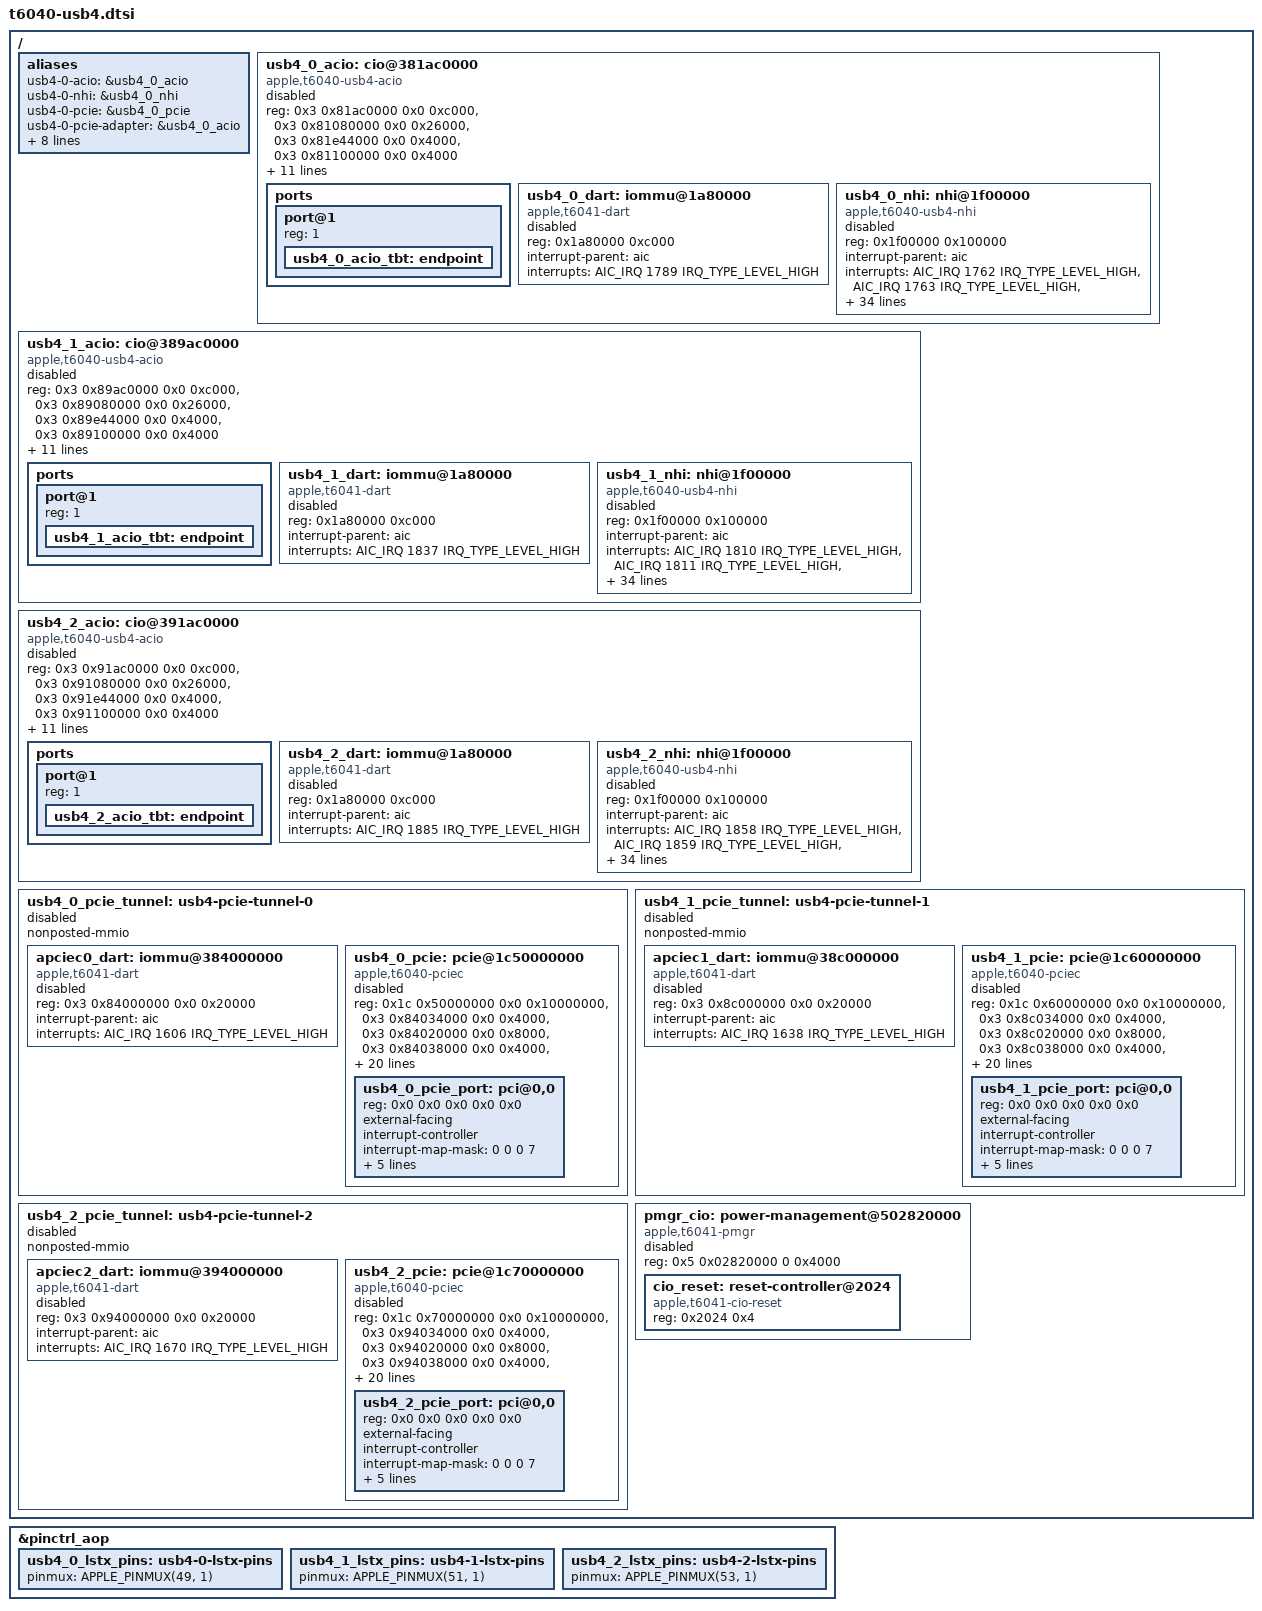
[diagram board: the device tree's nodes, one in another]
// SPDX-License-Identifier: GPL-2.0+ OR MIT
/*
 * T6040 USB4/PCIe-C resource description.
 *
 * Every node is disabled here; a board enables the routers it has qualified.
 */

/ {
	aliases {
		usb4-0-acio = &usb4_0_acio;
		usb4-0-nhi = &usb4_0_nhi;
		usb4-0-pcie = &usb4_0_pcie;
		usb4-0-pcie-adapter = &usb4_0_acio;
		usb4-1-acio = &usb4_1_acio;
		usb4-1-nhi = &usb4_1_nhi;
		usb4-1-pcie = &usb4_1_pcie;
		usb4-1-pcie-adapter = &usb4_1_acio;
		usb4-2-acio = &usb4_2_acio;
		usb4-2-nhi = &usb4_2_nhi;
		usb4-2-pcie = &usb4_2_pcie;
		usb4-2-pcie-adapter = &usb4_2_acio;
	};

	usb4_0_acio: cio@381ac0000 {
		compatible = "apple,t6040-usb4-acio";
		reg = <0x3 0x81ac0000 0x0 0xc000>,
		      <0x3 0x81080000 0x0 0x26000>,
		      <0x3 0x81e44000 0x0 0x4000>,
		      <0x3 0x81100000 0x0 0x4000>;
		reg-names = "rc", "sram", "pcie-adapter", "cpu";
		interrupt-parent = <&aic>;
		interrupts = <AIC_IRQ 1791 IRQ_TYPE_LEVEL_HIGH>;
		interrupt-names = "sram-parity";
		mboxes = <&usb4_0_mbox>;
		resets = <&cio_reset 0>;
		pinctrl-names = "lstx";
		pinctrl-0 = <&usb4_0_lstx_pins>;
		lstx-gpios = <&pinctrl_aop 49 GPIO_ACTIVE_HIGH>;
		power-domains = <&ps_atc0_cio>, <&ps_atc0_cio_pcie>,
				<&ps_atc0_cio_usb>, <&ps_atc0_pcie>;
		thunderbolt-switch;
		apple,pcie-tunnel = <&usb4_0_pcie_tunnel>;
		#address-cells = <1>;
		#size-cells = <1>;
		ranges = <0x0 0x3 0x80000000 0x2000000>;
		nonposted-mmio;
		status = "disabled";

		ports {
			#address-cells = <1>;
			#size-cells = <0>;

			port@1 {
				reg = <1>;
				usb4_0_acio_tbt: endpoint { };
			};
		};

		usb4_0_dart: iommu@1a80000 {
			compatible = "apple,t6041-dart", "apple,t8110-dart";
			reg = <0x1a80000 0xc000>;
			#iommu-cells = <1>;
			interrupt-parent = <&aic>;
			interrupts = <AIC_IRQ 1789 IRQ_TYPE_LEVEL_HIGH>;
			status = "disabled";
		};

		usb4_0_nhi: nhi@1f00000 {
			compatible = "apple,t6040-usb4-nhi";
			reg = <0x1f00000 0x100000>;
			reg-names = "nhi";
			interrupt-parent = <&aic>;
			interrupts = <AIC_IRQ 1762 IRQ_TYPE_LEVEL_HIGH>,
				     <AIC_IRQ 1763 IRQ_TYPE_LEVEL_HIGH>,
				     <AIC_IRQ 1764 IRQ_TYPE_LEVEL_HIGH>,
				     <AIC_IRQ 1765 IRQ_TYPE_LEVEL_HIGH>,
				     <AIC_IRQ 1766 IRQ_TYPE_LEVEL_HIGH>,
				     <AIC_IRQ 1767 IRQ_TYPE_LEVEL_HIGH>,
				     <AIC_IRQ 1768 IRQ_TYPE_LEVEL_HIGH>,
				     <AIC_IRQ 1769 IRQ_TYPE_LEVEL_HIGH>,
				     <AIC_IRQ 1770 IRQ_TYPE_LEVEL_HIGH>,
				     <AIC_IRQ 1771 IRQ_TYPE_LEVEL_HIGH>,
				     <AIC_IRQ 1772 IRQ_TYPE_LEVEL_HIGH>,
				     <AIC_IRQ 1773 IRQ_TYPE_LEVEL_HIGH>,
				     <AIC_IRQ 1774 IRQ_TYPE_LEVEL_HIGH>,
				     <AIC_IRQ 1775 IRQ_TYPE_LEVEL_HIGH>,
				     <AIC_IRQ 1776 IRQ_TYPE_LEVEL_HIGH>,
				     <AIC_IRQ 1777 IRQ_TYPE_LEVEL_HIGH>,
				     <AIC_IRQ 1778 IRQ_TYPE_LEVEL_HIGH>,
				     <AIC_IRQ 1779 IRQ_TYPE_LEVEL_HIGH>,
				     <AIC_IRQ 1780 IRQ_TYPE_LEVEL_HIGH>,
				     <AIC_IRQ 1781 IRQ_TYPE_LEVEL_HIGH>,
				     <AIC_IRQ 1782 IRQ_TYPE_LEVEL_HIGH>,
				     <AIC_IRQ 1783 IRQ_TYPE_LEVEL_HIGH>,
				     <AIC_IRQ 1784 IRQ_TYPE_LEVEL_HIGH>,
				     <AIC_IRQ 1785 IRQ_TYPE_LEVEL_HIGH>;
			interrupt-names = "txring0", "txring1", "txring2", "txring3",
					  "txring4", "txring5", "txring6", "txring7",
					  "txring8", "txring9", "txring10", "txring11",
					  "rxring0", "rxring1", "rxring2", "rxring3",
					  "rxring4", "rxring5", "rxring6", "rxring7",
					  "rxring8", "rxring9", "rxring10", "rxring11";
			iommus = <&usb4_0_dart 0>, <&usb4_0_dart 1>,
				 <&usb4_0_dart 2>, <&usb4_0_dart 3>,
				 <&usb4_0_dart 4>, <&usb4_0_dart 5>,
				 <&usb4_0_dart 6>, <&usb4_0_dart 7>,
				 <&usb4_0_dart 8>, <&usb4_0_dart 9>,
				 <&usb4_0_dart 10>, <&usb4_0_dart 11>,
				 <&usb4_0_dart 16>, <&usb4_0_dart 17>,
				 <&usb4_0_dart 18>, <&usb4_0_dart 19>,
				 <&usb4_0_dart 20>, <&usb4_0_dart 21>,
				 <&usb4_0_dart 22>, <&usb4_0_dart 23>,
				 <&usb4_0_dart 24>, <&usb4_0_dart 25>,
				 <&usb4_0_dart 26>, <&usb4_0_dart 27>;
			/* To be filled by the loader. */
			apple,thunderbolt-drom = [00];
			status = "disabled";
		};
	};

	usb4_1_acio: cio@389ac0000 {
		compatible = "apple,t6040-usb4-acio";
		reg = <0x3 0x89ac0000 0x0 0xc000>,
		      <0x3 0x89080000 0x0 0x26000>,
		      <0x3 0x89e44000 0x0 0x4000>,
		      <0x3 0x89100000 0x0 0x4000>;
		reg-names = "rc", "sram", "pcie-adapter", "cpu";
		interrupt-parent = <&aic>;
		interrupts = <AIC_IRQ 1839 IRQ_TYPE_LEVEL_HIGH>;
		interrupt-names = "sram-parity";
		mboxes = <&usb4_1_mbox>;
		resets = <&cio_reset 1>;
		pinctrl-names = "lstx";
		pinctrl-0 = <&usb4_1_lstx_pins>;
		lstx-gpios = <&pinctrl_aop 51 GPIO_ACTIVE_HIGH>;
		power-domains = <&ps_atc1_cio>, <&ps_atc1_cio_pcie>,
				<&ps_atc1_cio_usb>, <&ps_atc1_pcie>;
		thunderbolt-switch;
		apple,pcie-tunnel = <&usb4_1_pcie_tunnel>;
		#address-cells = <1>;
		#size-cells = <1>;
		ranges = <0x0 0x3 0x88000000 0x2000000>;
		nonposted-mmio;
		status = "disabled";

		ports {
			#address-cells = <1>;
			#size-cells = <0>;

			port@1 {
				reg = <1>;
				usb4_1_acio_tbt: endpoint { };
			};
		};

		usb4_1_dart: iommu@1a80000 {
			compatible = "apple,t6041-dart", "apple,t8110-dart";
			reg = <0x1a80000 0xc000>;
			#iommu-cells = <1>;
			interrupt-parent = <&aic>;
			interrupts = <AIC_IRQ 1837 IRQ_TYPE_LEVEL_HIGH>;
			status = "disabled";
		};

		usb4_1_nhi: nhi@1f00000 {
			compatible = "apple,t6040-usb4-nhi";
			reg = <0x1f00000 0x100000>;
			reg-names = "nhi";
			interrupt-parent = <&aic>;
			interrupts = <AIC_IRQ 1810 IRQ_TYPE_LEVEL_HIGH>,
				     <AIC_IRQ 1811 IRQ_TYPE_LEVEL_HIGH>,
				     <AIC_IRQ 1812 IRQ_TYPE_LEVEL_HIGH>,
				     <AIC_IRQ 1813 IRQ_TYPE_LEVEL_HIGH>,
				     <AIC_IRQ 1814 IRQ_TYPE_LEVEL_HIGH>,
				     <AIC_IRQ 1815 IRQ_TYPE_LEVEL_HIGH>,
				     <AIC_IRQ 1816 IRQ_TYPE_LEVEL_HIGH>,
				     <AIC_IRQ 1817 IRQ_TYPE_LEVEL_HIGH>,
				     <AIC_IRQ 1818 IRQ_TYPE_LEVEL_HIGH>,
				     <AIC_IRQ 1819 IRQ_TYPE_LEVEL_HIGH>,
				     <AIC_IRQ 1820 IRQ_TYPE_LEVEL_HIGH>,
				     <AIC_IRQ 1821 IRQ_TYPE_LEVEL_HIGH>,
				     <AIC_IRQ 1822 IRQ_TYPE_LEVEL_HIGH>,
				     <AIC_IRQ 1823 IRQ_TYPE_LEVEL_HIGH>,
				     <AIC_IRQ 1824 IRQ_TYPE_LEVEL_HIGH>,
				     <AIC_IRQ 1825 IRQ_TYPE_LEVEL_HIGH>,
				     <AIC_IRQ 1826 IRQ_TYPE_LEVEL_HIGH>,
				     <AIC_IRQ 1827 IRQ_TYPE_LEVEL_HIGH>,
				     <AIC_IRQ 1828 IRQ_TYPE_LEVEL_HIGH>,
				     <AIC_IRQ 1829 IRQ_TYPE_LEVEL_HIGH>,
				     <AIC_IRQ 1830 IRQ_TYPE_LEVEL_HIGH>,
				     <AIC_IRQ 1831 IRQ_TYPE_LEVEL_HIGH>,
				     <AIC_IRQ 1832 IRQ_TYPE_LEVEL_HIGH>,
				     <AIC_IRQ 1833 IRQ_TYPE_LEVEL_HIGH>;
			interrupt-names = "txring0", "txring1", "txring2", "txring3",
					  "txring4", "txring5", "txring6", "txring7",
					  "txring8", "txring9", "txring10", "txring11",
					  "rxring0", "rxring1", "rxring2", "rxring3",
					  "rxring4", "rxring5", "rxring6", "rxring7",
					  "rxring8", "rxring9", "rxring10", "rxring11";
			iommus = <&usb4_1_dart 0>, <&usb4_1_dart 1>,
				 <&usb4_1_dart 2>, <&usb4_1_dart 3>,
				 <&usb4_1_dart 4>, <&usb4_1_dart 5>,
				 <&usb4_1_dart 6>, <&usb4_1_dart 7>,
				 <&usb4_1_dart 8>, <&usb4_1_dart 9>,
				 <&usb4_1_dart 10>, <&usb4_1_dart 11>,
				 <&usb4_1_dart 16>, <&usb4_1_dart 17>,
				 <&usb4_1_dart 18>, <&usb4_1_dart 19>,
				 <&usb4_1_dart 20>, <&usb4_1_dart 21>,
				 <&usb4_1_dart 22>, <&usb4_1_dart 23>,
				 <&usb4_1_dart 24>, <&usb4_1_dart 25>,
				 <&usb4_1_dart 26>, <&usb4_1_dart 27>;
			/* To be filled by the loader. */
			apple,thunderbolt-drom = [00];
			status = "disabled";
		};
	};

	usb4_2_acio: cio@391ac0000 {
		compatible = "apple,t6040-usb4-acio";
		reg = <0x3 0x91ac0000 0x0 0xc000>,
		      <0x3 0x91080000 0x0 0x26000>,
		      <0x3 0x91e44000 0x0 0x4000>,
		      <0x3 0x91100000 0x0 0x4000>;
		reg-names = "rc", "sram", "pcie-adapter", "cpu";
		interrupt-parent = <&aic>;
		interrupts = <AIC_IRQ 1887 IRQ_TYPE_LEVEL_HIGH>;
		interrupt-names = "sram-parity";
		mboxes = <&usb4_2_mbox>;
		resets = <&cio_reset 2>;
		pinctrl-names = "lstx";
		pinctrl-0 = <&usb4_2_lstx_pins>;
		lstx-gpios = <&pinctrl_aop 53 GPIO_ACTIVE_HIGH>;
		power-domains = <&ps_atc2_cio>, <&ps_atc2_cio_pcie>,
				<&ps_atc2_cio_usb>, <&ps_atc2_pcie>;
		thunderbolt-switch;
		apple,pcie-tunnel = <&usb4_2_pcie_tunnel>;
		#address-cells = <1>;
		#size-cells = <1>;
		ranges = <0x0 0x3 0x90000000 0x2000000>;
		nonposted-mmio;
		status = "disabled";

		ports {
			#address-cells = <1>;
			#size-cells = <0>;

			port@1 {
				reg = <1>;
				usb4_2_acio_tbt: endpoint { };
			};
		};

		usb4_2_dart: iommu@1a80000 {
			compatible = "apple,t6041-dart", "apple,t8110-dart";
			reg = <0x1a80000 0xc000>;
			#iommu-cells = <1>;
			interrupt-parent = <&aic>;
			interrupts = <AIC_IRQ 1885 IRQ_TYPE_LEVEL_HIGH>;
			status = "disabled";
		};

		usb4_2_nhi: nhi@1f00000 {
			compatible = "apple,t6040-usb4-nhi";
			reg = <0x1f00000 0x100000>;
			reg-names = "nhi";
			interrupt-parent = <&aic>;
			interrupts = <AIC_IRQ 1858 IRQ_TYPE_LEVEL_HIGH>,
				     <AIC_IRQ 1859 IRQ_TYPE_LEVEL_HIGH>,
				     <AIC_IRQ 1860 IRQ_TYPE_LEVEL_HIGH>,
				     <AIC_IRQ 1861 IRQ_TYPE_LEVEL_HIGH>,
				     <AIC_IRQ 1862 IRQ_TYPE_LEVEL_HIGH>,
				     <AIC_IRQ 1863 IRQ_TYPE_LEVEL_HIGH>,
				     <AIC_IRQ 1864 IRQ_TYPE_LEVEL_HIGH>,
				     <AIC_IRQ 1865 IRQ_TYPE_LEVEL_HIGH>,
				     <AIC_IRQ 1866 IRQ_TYPE_LEVEL_HIGH>,
				     <AIC_IRQ 1867 IRQ_TYPE_LEVEL_HIGH>,
				     <AIC_IRQ 1868 IRQ_TYPE_LEVEL_HIGH>,
				     <AIC_IRQ 1869 IRQ_TYPE_LEVEL_HIGH>,
				     <AIC_IRQ 1870 IRQ_TYPE_LEVEL_HIGH>,
				     <AIC_IRQ 1871 IRQ_TYPE_LEVEL_HIGH>,
				     <AIC_IRQ 1872 IRQ_TYPE_LEVEL_HIGH>,
				     <AIC_IRQ 1873 IRQ_TYPE_LEVEL_HIGH>,
				     <AIC_IRQ 1874 IRQ_TYPE_LEVEL_HIGH>,
				     <AIC_IRQ 1875 IRQ_TYPE_LEVEL_HIGH>,
				     <AIC_IRQ 1876 IRQ_TYPE_LEVEL_HIGH>,
				     <AIC_IRQ 1877 IRQ_TYPE_LEVEL_HIGH>,
				     <AIC_IRQ 1878 IRQ_TYPE_LEVEL_HIGH>,
				     <AIC_IRQ 1879 IRQ_TYPE_LEVEL_HIGH>,
				     <AIC_IRQ 1880 IRQ_TYPE_LEVEL_HIGH>,
				     <AIC_IRQ 1881 IRQ_TYPE_LEVEL_HIGH>;
			interrupt-names = "txring0", "txring1", "txring2", "txring3",
					  "txring4", "txring5", "txring6", "txring7",
					  "txring8", "txring9", "txring10", "txring11",
					  "rxring0", "rxring1", "rxring2", "rxring3",
					  "rxring4", "rxring5", "rxring6", "rxring7",
					  "rxring8", "rxring9", "rxring10", "rxring11";
			iommus = <&usb4_2_dart 0>, <&usb4_2_dart 1>,
				 <&usb4_2_dart 2>, <&usb4_2_dart 3>,
				 <&usb4_2_dart 4>, <&usb4_2_dart 5>,
				 <&usb4_2_dart 6>, <&usb4_2_dart 7>,
				 <&usb4_2_dart 8>, <&usb4_2_dart 9>,
				 <&usb4_2_dart 10>, <&usb4_2_dart 11>,
				 <&usb4_2_dart 16>, <&usb4_2_dart 17>,
				 <&usb4_2_dart 18>, <&usb4_2_dart 19>,
				 <&usb4_2_dart 20>, <&usb4_2_dart 21>,
				 <&usb4_2_dart 22>, <&usb4_2_dart 23>,
				 <&usb4_2_dart 24>, <&usb4_2_dart 25>,
				 <&usb4_2_dart 26>, <&usb4_2_dart 27>;
			/* To be filled by the loader. */
			apple,thunderbolt-drom = [00];
			status = "disabled";
		};
	};

	usb4_0_pcie_tunnel: usb4-pcie-tunnel-0 {
		#address-cells = <2>;
		#size-cells = <2>;
		ranges;
		nonposted-mmio;
		status = "disabled";

		apciec0_dart: iommu@384000000 {
			compatible = "apple,t6041-dart", "apple,t8110-dart";
			reg = <0x3 0x84000000 0x0 0x20000>;
			interrupt-parent = <&aic>;
			interrupts = <AIC_IRQ 1606 IRQ_TYPE_LEVEL_HIGH>;
			#iommu-cells = <1>;
			status = "disabled";
		};

		usb4_0_pcie: pcie@1c50000000 {
			compatible = "apple,t6040-pciec";
			device_type = "pci";
			reg = <0x1c 0x50000000 0x0 0x10000000>,
			      <0x3 0x84034000 0x0 0x4000>,
			      <0x3 0x84020000 0x0 0x8000>,
			      <0x3 0x84038000 0x0 0x4000>,
			      <0x3 0x84060000 0x0 0x4000>,
			      <0x3 0x80020000 0x0 0x4000>,
			      <0x3 0x8402c000 0x0 0x4000>,
			      <0x3 0x84028000 0x0 0x4000>;
			reg-names = "config", "rc", "port0", "fabric", "debug",
				    "ioa", "ltssm", "intr2axi";
			interrupt-parent = <&aic>;
			interrupts = <AIC_IRQ 1605 IRQ_TYPE_LEVEL_HIGH>,
				     <AIC_IRQ 1608 IRQ_TYPE_LEVEL_HIGH>,
				     <AIC_IRQ 1609 IRQ_TYPE_LEVEL_HIGH>,
				     <AIC_IRQ 1610 IRQ_TYPE_LEVEL_HIGH>,
				     <AIC_IRQ 1611 IRQ_TYPE_LEVEL_HIGH>,
				     <AIC_IRQ 1612 IRQ_TYPE_LEVEL_HIGH>;
			interrupt-names = "port", "intx-a", "intx-b", "intx-c",
					  "intx-d", "parity";
			power-domains = <&ps_atc0_pcie>;
			msi-controller;
			msi-parent = <&usb4_0_pcie>;
			msi-ranges = <&aic AIC_IRQ 2103 IRQ_TYPE_EDGE_RISING 32>;
			apple,msi-vector-base = <0x20>;
			iommu-map = <0x0 &apciec0_dart 0x0 0x100>;
			iommu-map-mask = <0xff>;
			bus-range = <0x0 0x80>;
			#address-cells = <3>;
			#size-cells = <2>;
			ranges = <0x43000000 0x8 0x0 0x8 0x0 0x2 0x0>,
				 <0x02000000 0x0 0x100000 0xa 0x100000 0x0 0x3ff00000>,
				 <0x42000000 0x0 0x40000000 0xa 0x40000000 0x0 0x40000000>;
			status = "disabled";

			usb4_0_pcie_port: pci@0,0 {
				device_type = "pci";
				reg = <0x0 0x0 0x0 0x0 0x0>;
				external-facing;
				#address-cells = <3>;
				#size-cells = <2>;
				ranges;
				interrupt-controller;
				#interrupt-cells = <1>;
				interrupt-map-mask = <0 0 0 7>;
				interrupt-map = <0 0 0 1 &usb4_0_pcie_port 0 0 0 0>,
						<0 0 0 2 &usb4_0_pcie_port 0 0 0 1>,
						<0 0 0 3 &usb4_0_pcie_port 0 0 0 2>,
						<0 0 0 4 &usb4_0_pcie_port 0 0 0 3>;
			};
		};
	};

	usb4_1_pcie_tunnel: usb4-pcie-tunnel-1 {
		#address-cells = <2>;
		#size-cells = <2>;
		ranges;
		nonposted-mmio;
		status = "disabled";

		apciec1_dart: iommu@38c000000 {
			compatible = "apple,t6041-dart", "apple,t8110-dart";
			reg = <0x3 0x8c000000 0x0 0x20000>;
			interrupt-parent = <&aic>;
			interrupts = <AIC_IRQ 1638 IRQ_TYPE_LEVEL_HIGH>;
			#iommu-cells = <1>;
			status = "disabled";
		};

		usb4_1_pcie: pcie@1c60000000 {
			compatible = "apple,t6040-pciec";
			device_type = "pci";
			reg = <0x1c 0x60000000 0x0 0x10000000>,
			      <0x3 0x8c034000 0x0 0x4000>,
			      <0x3 0x8c020000 0x0 0x8000>,
			      <0x3 0x8c038000 0x0 0x4000>,
			      <0x3 0x8c060000 0x0 0x4000>,
			      <0x3 0x88020000 0x0 0x4000>,
			      <0x3 0x8c02c000 0x0 0x4000>,
			      <0x3 0x8c028000 0x0 0x4000>;
			reg-names = "config", "rc", "port0", "fabric", "debug",
				    "ioa", "ltssm", "intr2axi";
			interrupt-parent = <&aic>;
			interrupts = <AIC_IRQ 1637 IRQ_TYPE_LEVEL_HIGH>,
				     <AIC_IRQ 1640 IRQ_TYPE_LEVEL_HIGH>,
				     <AIC_IRQ 1641 IRQ_TYPE_LEVEL_HIGH>,
				     <AIC_IRQ 1642 IRQ_TYPE_LEVEL_HIGH>,
				     <AIC_IRQ 1643 IRQ_TYPE_LEVEL_HIGH>,
				     <AIC_IRQ 1644 IRQ_TYPE_LEVEL_HIGH>;
			interrupt-names = "port", "intx-a", "intx-b", "intx-c",
					  "intx-d", "parity";
			power-domains = <&ps_atc1_pcie>;
			msi-controller;
			msi-parent = <&usb4_1_pcie>;
			msi-ranges = <&aic AIC_IRQ 2135 IRQ_TYPE_EDGE_RISING 32>;
			apple,msi-vector-base = <0x40>;
			iommu-map = <0x0 &apciec1_dart 0x0 0x100>;
			iommu-map-mask = <0xff>;
			bus-range = <0x0 0x80>;
			#address-cells = <3>;
			#size-cells = <2>;
			ranges = <0x43000000 0xc 0x0 0xc 0x0 0x2 0x0>,
				 <0x02000000 0x0 0x100000 0xe 0x100000 0x0 0x3ff00000>,
				 <0x42000000 0x0 0x40000000 0xe 0x40000000 0x0 0x40000000>;
			status = "disabled";

			usb4_1_pcie_port: pci@0,0 {
				device_type = "pci";
				reg = <0x0 0x0 0x0 0x0 0x0>;
				external-facing;
				#address-cells = <3>;
				#size-cells = <2>;
				ranges;
				interrupt-controller;
				#interrupt-cells = <1>;
				interrupt-map-mask = <0 0 0 7>;
				interrupt-map = <0 0 0 1 &usb4_1_pcie_port 0 0 0 0>,
						<0 0 0 2 &usb4_1_pcie_port 0 0 0 1>,
						<0 0 0 3 &usb4_1_pcie_port 0 0 0 2>,
						<0 0 0 4 &usb4_1_pcie_port 0 0 0 3>;
			};
		};
	};

	usb4_2_pcie_tunnel: usb4-pcie-tunnel-2 {
		#address-cells = <2>;
		#size-cells = <2>;
		ranges;
		nonposted-mmio;
		status = "disabled";

		apciec2_dart: iommu@394000000 {
			compatible = "apple,t6041-dart", "apple,t8110-dart";
			reg = <0x3 0x94000000 0x0 0x20000>;
			interrupt-parent = <&aic>;
			interrupts = <AIC_IRQ 1670 IRQ_TYPE_LEVEL_HIGH>;
			#iommu-cells = <1>;
			status = "disabled";
		};

		usb4_2_pcie: pcie@1c70000000 {
			compatible = "apple,t6040-pciec";
			device_type = "pci";
			reg = <0x1c 0x70000000 0x0 0x10000000>,
			      <0x3 0x94034000 0x0 0x4000>,
			      <0x3 0x94020000 0x0 0x8000>,
			      <0x3 0x94038000 0x0 0x4000>,
			      <0x3 0x94060000 0x0 0x4000>,
			      <0x3 0x90020000 0x0 0x4000>,
			      <0x3 0x9402c000 0x0 0x4000>,
			      <0x3 0x94028000 0x0 0x4000>;
			reg-names = "config", "rc", "port0", "fabric", "debug",
				    "ioa", "ltssm", "intr2axi";
			interrupt-parent = <&aic>;
			interrupts = <AIC_IRQ 1669 IRQ_TYPE_LEVEL_HIGH>,
				     <AIC_IRQ 1672 IRQ_TYPE_LEVEL_HIGH>,
				     <AIC_IRQ 1673 IRQ_TYPE_LEVEL_HIGH>,
				     <AIC_IRQ 1674 IRQ_TYPE_LEVEL_HIGH>,
				     <AIC_IRQ 1675 IRQ_TYPE_LEVEL_HIGH>,
				     <AIC_IRQ 1676 IRQ_TYPE_LEVEL_HIGH>;
			interrupt-names = "port", "intx-a", "intx-b", "intx-c",
					  "intx-d", "parity";
			power-domains = <&ps_atc2_pcie>;
			msi-controller;
			msi-parent = <&usb4_2_pcie>;
			msi-ranges = <&aic AIC_IRQ 2167 IRQ_TYPE_EDGE_RISING 32>;
			apple,msi-vector-base = <0x60>;
			iommu-map = <0x0 &apciec2_dart 0x0 0x100>;
			iommu-map-mask = <0xff>;
			bus-range = <0x0 0x80>;
			#address-cells = <3>;
			#size-cells = <2>;
			ranges = <0x43000000 0x10 0x0 0x10 0x0 0x2 0x0>,
				 <0x02000000 0x0 0x100000 0x12 0x100000 0x0 0x3ff00000>,
				 <0x42000000 0x0 0x40000000 0x12 0x40000000 0x0 0x40000000>;
			status = "disabled";

			usb4_2_pcie_port: pci@0,0 {
				device_type = "pci";
				reg = <0x0 0x0 0x0 0x0 0x0>;
				external-facing;
				#address-cells = <3>;
				#size-cells = <2>;
				ranges;
				interrupt-controller;
				#interrupt-cells = <1>;
				interrupt-map-mask = <0 0 0 7>;
				interrupt-map = <0 0 0 1 &usb4_2_pcie_port 0 0 0 0>,
						<0 0 0 2 &usb4_2_pcie_port 0 0 0 1>,
						<0 0 0 3 &usb4_2_pcie_port 0 0 0 2>,
						<0 0 0 4 &usb4_2_pcie_port 0 0 0 3>;
			};
		};
	};
};

/ {
	/* ADT pmgr reg[44]: AppleT6041PMGR::enableCioReconfig at +0x2024. */
	pmgr_cio: power-management@502820000 {
		compatible = "apple,t6041-pmgr", "apple,t8103-pmgr", "syscon", "simple-mfd";
		#address-cells = <1>;
		#size-cells = <1>;
		reg = <0x5 0x02820000 0 0x4000>;
		/* Enabled together with the routers. */
		status = "disabled";

		cio_reset: reset-controller@2024 {
			compatible = "apple,t6041-cio-reset";
			reg = <0x2024 0x4>;
			#reset-cells = <1>;
		};
	};
};

&pinctrl_aop {
	/* ADT acioN gpio-lstx. */
	usb4_0_lstx_pins: usb4-0-lstx-pins {
		pinmux = <APPLE_PINMUX(49, 1)>;
	};

	usb4_1_lstx_pins: usb4-1-lstx-pins {
		pinmux = <APPLE_PINMUX(51, 1)>;
	};

	usb4_2_lstx_pins: usb4-2-lstx-pins {
		pinmux = <APPLE_PINMUX(53, 1)>;
	};
};
